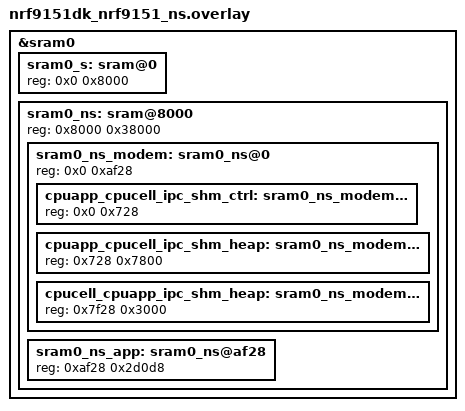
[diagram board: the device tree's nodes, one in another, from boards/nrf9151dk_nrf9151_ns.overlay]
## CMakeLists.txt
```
#
# Copyright (c) 2026 Nordic Semiconductor ASA
#
# SPDX-License-Identifier: LicenseRef-Nordic-5-Clause
#

cmake_minimum_required(VERSION 3.20.0)

find_package(Zephyr REQUIRED HINTS $ENV{ZEPHYR_BASE})
project(dect_tether_ipv6)

target_include_directories(app PRIVATE
  ${ZEPHYR_NRF_MODULE_DIR}/subsys/net/lib/dect/dect_tether_ipv6
)

target_sources(app PRIVATE src/main.c)
target_sources_ifdef(CONFIG_SAMPLE_DECT_TETHER_IPV6_MDNS_DNS_SD app PRIVATE
  src/mdns_dns_sd_listen.c
)
```

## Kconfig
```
#
# Copyright (c) 2026 Nordic Semiconductor ASA
#
# SPDX-License-Identifier: LicenseRef-Nordic-5-Clause
#

source "Kconfig.zephyr"

config SAMPLE_DECT_TETHER_IPV6_MDNS_DNS_SD
	bool "Advertise _dect-nr._udp on dect0 (mDNS DNS-SD, like dect_shell)"
	depends on MDNS_RESPONDER_DNS_SD
	help
	  Binds a UDP socket on the DECT interface and registers mDNS DNS-SD for
	  _dect-nr._udp.local so peers on DECT can browse this device (e.g. avahi-browse).
	  Enable CONFIG_NET_HOSTNAME and stack options via mdns.conf.

if SAMPLE_DECT_TETHER_IPV6_MDNS_DNS_SD

config SAMPLE_DECT_TETHER_IPV6_MDNS_DNS_SD_PORT
	int "UDP port for mDNS DNS-SD stub socket on dect0"
	default 4700
	range 1 65535
	help
	  Port bound on dect0 so dns_sd port_in_use checks succeed. Must match dns_sd_rec.port.

endif # SAMPLE_DECT_TETHER_IPV6_MDNS_DNS_SD

module = SAMPLE_DECT_TETHER_IPV6
module-str = DECT IPv6 tethering sample
source "${ZEPHYR_BASE}/subsys/logging/Kconfig.template.log_config"
```

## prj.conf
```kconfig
#
# Copyright (c) 2026 Nordic Semiconductor ASA
#
# SPDX-License-Identifier: LicenseRef-Nordic-5-Clause
#

CONFIG_TFM_PROFILE_TYPE_MINIMAL=y

CONFIG_DECT=y
CONFIG_DECT_DEFAULT_DEV_TYPE_PT=y
CONFIG_DECT_CLUSTER_MAX_CHILD_ASSOCIATION_COUNT=2

CONFIG_NRF_MODEM_LIB=y
CONFIG_NRF_MODEM_LINK_BINARY_DECT=y
CONFIG_NRF_MODEM_LIB_ON_FAULT_APPLICATION_SPECIFIC=y

CONFIG_DECT_MDM=y
CONFIG_DECT_MDM_DRIVER_NRF=y
CONFIG_DECT_MDM_NRF_CTRL_THREAD_STACK_SIZE=3584

CONFIG_NETWORKING=y
CONFIG_NET_NATIVE=y
CONFIG_NET_IPV4=n
CONFIG_NET_IPV6=y
CONFIG_NET_UDP=y
CONFIG_NET_MGMT=y
CONFIG_NET_MGMT_EVENT=y
CONFIG_NET_MGMT_EVENT_INFO=y
CONFIG_NET_MGMT_EVENT_INFO_DEFAULT_DATA_SIZE=208

CONFIG_NET_L2_DECT=y
CONFIG_NET_L2_DECT_MGMT=y
CONFIG_NET_L2_DECT_BR=n
CONFIG_NET_CONNECTION_MANAGER=y
CONFIG_NET_CONNECTION_MANAGER_MONITOR_STACK_SIZE=2560
CONFIG_NET_L2_DECT_CONN_MGR_AUTO_CONNECT=y
CONFIG_NET_L2_DECT_CONN_MGR_CONNECTION_PERSISTENCE=y

CONFIG_NET_L2_DECT_ULA=y
CONFIG_NET_L2_DECT_ULA_PREFIX="fdde:ad00:0000::"

CONFIG_NET_IPV6_FORWARDING=y

CONFIG_DECT_TETHER_IPV6_LIB=y
CONFIG_DECT_TETHER_IPV6_LOG_LEVEL_INF=y

CONFIG_MODEM_ANTENNA=n
CONFIG_MODEM_INFO=y
CONFIG_MODEM_INFO_ADD_NETWORK=n
CONFIG_MODEM_INFO_ADD_SIM=n

CONFIG_NET_SOCKETS=y
CONFIG_NET_SOCKETS_OFFLOAD=n
CONFIG_POSIX_API=y
CONFIG_NET_IF_MAX_IPV6_COUNT=6
CONFIG_NET_IF_UNICAST_IPV6_ADDR_COUNT=6
CONFIG_NET_IF_MCAST_IPV6_ADDR_COUNT=10
CONFIG_NET_IF_IPV6_PREFIX_COUNT=4
CONFIG_NET_INTERFACE_NAME=y
CONFIG_NET_MAX_CONTEXTS=12
CONFIG_NET_MAX_CONN=12

CONFIG_NET_RX_STACK_SIZE=4096
CONFIG_NET_TX_STACK_SIZE=4096
CONFIG_SYSTEM_WORKQUEUE_STACK_SIZE=8192

CONFIG_NET_BUF=y
CONFIG_NET_BUF_DATA_SIZE=128

CONFIG_NET_PKT_RX_COUNT=32
CONFIG_NET_PKT_TX_COUNT=64
CONFIG_NET_BUF_RX_COUNT=32
CONFIG_NET_BUF_TX_COUNT=64
CONFIG_NET_BUF_POOL_USAGE=y

CONFIG_NET_IPV6_NBR_CACHE=y
CONFIG_NET_IPV6_MAX_NEIGHBORS=10
CONFIG_NET_IPV6_ND=y

CONFIG_NET_MGMT_EVENT_STACK_SIZE=4608
CONFIG_NET_MGMT_EVENT_QUEUE_SIZE=30
CONFIG_NET_MGMT_EVENT_QUEUE_TIMEOUT=5000

CONFIG_NET_STATISTICS=y

CONFIG_SHELL=y
CONFIG_GETOPT_LONG=y
CONFIG_SHELL_PROMPT_UART="dect_tether_v6:~$ "
CONFIG_SHELL_BACKEND_SERIAL=y
CONFIG_SHELL_STACK_SIZE=9216
CONFIG_SHELL_CMD_BUFF_SIZE=4096
CONFIG_SHELL_ARGC_MAX=40
CONFIG_SHELL_BACKEND_SERIAL_RX_RING_BUFFER_SIZE=512
CONFIG_SHELL_BACKEND_SERIAL_API_INTERRUPT_DRIVEN=y
CONFIG_NET_SHELL=y
CONFIG_DECT_L2_SHELL_LIB=y
CONFIG_SHELL_LOG_BACKEND=y
CONFIG_LOG_BACKEND_UART=n

CONFIG_NET_DRIVERS=y
CONFIG_SERIAL=y

CONFIG_FLASH=y
CONFIG_FLASH_MAP=y
CONFIG_MPU_ALLOW_FLASH_WRITE=y
CONFIG_NVS=y
CONFIG_SETTINGS=y
CONFIG_SETTINGS_NVS=y

CONFIG_MAIN_STACK_SIZE=4096
CONFIG_ISR_STACK_SIZE=2048
CONFIG_HEAP_MEM_POOL_SIZE=25600
CONFIG_LOG=y
CONFIG_ASSERT=y

CONFIG_DK_LIBRARY=y
```

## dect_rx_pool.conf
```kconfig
# Copyright (c) 2026 Nordic Semiconductor ASA
# SPDX-License-Identifier: LicenseRef-Nordic-5-Clause
#
# DECT-private RX net_pkt/net_buf pool for dect_tether_ipv6.
#
# Append last in EXTRA_CONF_FILE, e.g.
#   eth_common.conf;eth_w5500.conf;dect_rx_pool.conf
#
# Why: this sample acts as the PT — DECT TX is the hot path (PC eth0 RX ->
# DECT TX uplink to FT), so the modem SHMEM split in prj.conf is
# TX-heavy. However, sustained PC->server uplink generates back-to-back
# TCP ACK bursts that arrive as small (60-96 B) DECT RX frames; those
# bursts saturate the private slab faster than the DLC RX thread can
# drain it. Sizing here is for burst depth (PKT_COUNT), not byte volume —
# fragment count can stay close to 1:1 since ACK-sized frames fit in one
# 256 B fragment.
#
# Tune _PKT_COUNT / _BUF_COUNT / _BUF_SIZE if "dect_mdm rx_pool" shows
# MaxUsed == Total under sustained PC->server traffic.
#
# Runtime inspection:
#   uart:~$ dect_mdm rx_pool

CONFIG_DECT_MDM_RX_PRIVATE_POOL=y

CONFIG_DECT_MDM_RX_PRIVATE_PKT_COUNT=35
CONFIG_DECT_MDM_RX_PRIVATE_BUF_COUNT=44
CONFIG_DECT_MDM_RX_PRIVATE_BUF_SIZE=128

# RX pipeline queues (event slab + msgq) must exceed PRIVATE_PKT_COUNT to
# avoid head-of-line blocking when the slab is fully in flight.
CONFIG_DECT_MDM_NRF_RX_EVENT_POOL_COUNT=40
CONFIG_DECT_MDM_NRF_RX_MSGQ_SIZE=40

# Visibility for the "dect_mdm rx_pool" shell:
CONFIG_NET_BUF_POOL_USAGE=y
CONFIG_MEM_SLAB_TRACE_MAX_UTILIZATION=y
```

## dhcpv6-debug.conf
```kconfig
# Copyright (c) 2026 Nordic Semiconductor ASA
#
# SPDX-License-Identifier: LicenseRef-Nordic-5-Clause
#
# DHCPv6 tether debugging: log each datagram received on UDP 547 and extra DBG
# lines from dect_tether_ipv6 (e.g. DHCP drops). Merge after prj.conf chain:
#
#   EXTRA_CONF_FILE="eth_common.conf;eth_w5500.conf;dhcpv6-debug.conf"
#
# Disable for production (Renew traffic can spam UART).

CONFIG_DECT_TETHER_IPV6_DHCPV6_RX_LOG=y
CONFIG_DECT_TETHER_IPV6_DHCPV6_TRACE=y
CONFIG_DECT_TETHER_IPV6_LOG_LEVEL_DBG=y
```

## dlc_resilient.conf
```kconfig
# Copyright (c) 2026 Nordic Semiconductor ASA
# SPDX-License-Identifier: LicenseRef-Nordic-5-Clause
#
# Loss-resilient DLC profile for dect_tether_ipv6 (PT side).
#
# Append last in EXTRA_CONF_FILE, e.g.:
#   eth_common.conf;eth_w5500.conf;dlc_resilient.conf
#
# Why: the stock DLC defaults (60 s lifetime, release on first discard)
# don't suit a tether deployment. Applied to the PT's flow_config[0]
# (PT->FT uplink) at association:
#
#   * SDU lifetime = 1.5 s (NRF_MODEM_DECT_DLC_SDU_LIFETIME_1_5_S = 21):
#     large enough to absorb a few DLC retransmission rounds without
#     dropping queued payload, small enough that a broken link surfaces
#     in seconds. Lower for latency-sensitive workloads instead.
#
#   * discard_release_assoc_count = 20: release only after 20 consecutive
#     DLC_DISCARD_TIMER_EXPIRED responses (counter resets on successful
#     TX); ~30 s worst case at the lifetime above. 0 = never release. The
#     matching FT-side overlay (dect_shell) uses 2.5 s; the two sides do
#     NOT need matching values.
#
# Both are runtime-tunable via the DECT L2 shell:
#   uart:~$ dect sett --dlc_sdu_lifetime 21
#   uart:~$ dect sett --dlc_discard_release_assoc_count 20
#   uart:~$ dect sett --read
#
# Valid sdu_lifetime: 1..31 (0.5 ms..60 s) or 255 for INFINITY.

CONFIG_DECT_MDM_NRF_DLC_SDU_LIFETIME=21
CONFIG_DECT_MDM_NRF_DLC_DISCARD_TIMER_RELEASE_ASSOC_COUNT=20
```

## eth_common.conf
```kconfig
# Copyright (c) 2026 Nordic Semiconductor ASA
#
# SPDX-License-Identifier: LicenseRef-Nordic-5-Clause
#
# Shared Ethernet shield Kconfig for dect_tether_ipv6 sample.
#
# EXTRA_CONF_FILE merge order (omit mDNS layers when not needed):
#   eth_common.conf -> eth_w5500.conf ->
#   mdns-common.conf -> mdns.conf -> eth_mdns.conf -> mdns_forward.conf -> optional extras
#
# From the sample directory (Ethernet only, no mDNS):
#   cd nrf/samples/dect/dect_tether_ipv6
#   west build -p -b nrf9151dk/nrf9151/ns --
#     -DSHIELD=arceli_eth_w5500
#     -DEXTRA_CONF_FILE="eth_common.conf;eth_w5500.conf"
#     -DEXTRA_DTC_OVERLAY_FILE=w5500-static-mac.overlay
#
# With mDNS responder on eth0 and dect0 (append mdns-common.conf, mdns.conf,
# eth_mdns.conf; add mdns_forward.conf for the eth0 <-> dect0 tap):
#   west build -p -b nrf9151dk/nrf9151/ns --
#     -DSHIELD=arceli_eth_w5500
#     -DEXTRA_CONF_FILE="eth_common.conf;eth_w5500.conf;mdns-common.conf;mdns.conf;eth_mdns.conf"
#     -DEXTRA_DTC_OVERLAY_FILE=w5500-static-mac.overlay
#
# For a random MAC each boot, use -DEXTRA_DTC_OVERLAY_FILE=w5500.overlay instead.
# For periodic unsolicited NA toward the tethered host, append eth_unsol_na.conf.
#
# Windows 11: RA-learned ::/0 often drops after ~30 s NUD. On the PC use a persistent
# static ::/0 (elevated PowerShell netsh) — see README "Optional static default
# gateway (Windows 11)". Or append eth_max_connectivity.conf (longer NUD interval).
#

# Unicast RA to RS source (RFC 4861); helps Windows install ::/0 at link-up.
CONFIG_DECT_TETHER_IPV6_RA_RS_UNICAST=y

CONFIG_SPI=y

CONFIG_ETH_DRIVER=y

CONFIG_NET_L2_ETHERNET=y
CONFIG_NET_L2_ETHERNET_MGMT=y

CONFIG_NET_L2_DECT_MTU=1500

# Using DECT and Ethernet RX threads
#CONFIG_NET_TC_TX_COUNT=0
#CONFIG_NET_TC_RX_COUNT=0

CONFIG_NET_PKT_TX_COUNT=10
CONFIG_NET_BUF_TX_COUNT=20

CONFIG_NET_PKT_RX_COUNT=30
CONFIG_NET_BUF_RX_COUNT=200

CONFIG_NET_LOG=y
CONFIG_ETHERNET_LOG_LEVEL_INF=y
CONFIG_NET_L2_ETHERNET_LOG_LEVEL_INF=y
# Surface "iface N pkt 0x... send failure status -E*" warnings (e.g. W5500 -EIO
# bursts) on this sample; otherwise net_if defaults below WRN and those
# warnings are silently dropped.
CONFIG_NET_IF_LOG_LEVEL_WRN=y

CONFIG_NET_MGMT_EVENT_QUEUE_SIZE=30

# dect0 + eth0
CONFIG_NET_IF_MAX_IPV6_COUNT=2
CONFIG_NET_IF_UNICAST_IPV6_ADDR_COUNT=3
CONFIG_NET_IF_IPV6_PREFIX_COUNT=3

CONFIG_DK_LIBRARY=n
```

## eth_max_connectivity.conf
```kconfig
# Copyright (c) 2026 Nordic Semiconductor ASA
#
# SPDX-License-Identifier: LicenseRef-Nordic-5-Clause
#
# Maximum-connectivity timer overlay for dect_tether_ipv6.
#
# Include AFTER eth_common.conf to override its test-oriented defaults:
#   -DEXTRA_CONF_FILE="eth_common.conf;eth_w5500.conf;eth_max_connectivity.conf"
#
# DO NOT include eth_unsol_na.conf together with this file unless you need it.
#
# Long REACHABLE_TIME and router/DHCP lifetimes reduce how often hosts run NUD
# and how often router_lifetime must be refreshed. Periodic multicast RAs
# (RA_UNSOLICIT_MS, default 60 s) remain the only RA refresh path.

# RFC 4861 §6.2.1 maximum: 3 600 000 ms.
CONFIG_DECT_TETHER_IPV6_RA_REACHABLE_TIME_MS=3600000

# RFC 4861 §4.2 maximum: 65535 s (~18 h).
CONFIG_DECT_TETHER_IPV6_RA_ROUTER_LIFETIME=65535

# DHCPv6 lease timers aligned with a long-running session.
CONFIG_DECT_TETHER_IPV6_DHCPV6_ADDR_PREFERRED_LIFETIME=86400
CONFIG_DECT_TETHER_IPV6_DHCPV6_ADDR_VALID_LIFETIME=172800
CONFIG_DECT_TETHER_IPV6_DHCPV6_T1=1800
CONFIG_DECT_TETHER_IPV6_DHCPV6_T2=2880

# PIO lifetimes matched to DHCPv6 address lifetimes.
CONFIG_DECT_TETHER_IPV6_RA_PIO_PREFERRED_LIFETIME=86400
CONFIG_DECT_TETHER_IPV6_RA_PIO_VALID_LIFETIME=172800
```

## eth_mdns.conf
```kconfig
# Copyright (c) 2026 Nordic Semiconductor ASA
#
# SPDX-License-Identifier: LicenseRef-Nordic-5-Clause
#
# mDNS-on-Ethernet tuning for dect_tether_ipv6. Merge after :file:`eth_common.conf`,
# shield-specific :file:`eth_*.conf`, :file:`mdns-common.conf`, and :file:`mdns.conf`.
#
# From the sample directory:
#   cd nrf/samples/dect/dect_tether_ipv6
#   west build -p -b nrf9151dk/nrf9151/ns --
#     -DSHIELD=arceli_eth_w5500
#     -DEXTRA_CONF_FILE="eth_common.conf;eth_w5500.conf;mdns-common.conf;mdns.conf;eth_mdns.conf"
#     -DEXTRA_DTC_OVERLAY_FILE=w5500-static-mac.overlay
#
# With eth0 <-> dect0 mDNS tap, also merge mdns_forward.conf after this file.

# Unicast DNS on eth0 + scoped mDNS on dect0 (order: unicast first, then mDNS).
CONFIG_DNS_RESOLVER_MAX_SERVERS=3
CONFIG_DNS_SERVER1="2001:4860:4860::8888%eth0"
CONFIG_DNS_SERVER2="2001:4860:4860::8844%eth0"
CONFIG_DNS_SERVER3="[ff02::fb]:5353%dect0"

# mdns-common.conf sets CONFIG_ZVFS_POLL_MAX=10; dect0 + eth0 and three scoped DNS
# servers need more dispatcher poll slots or dns_resolve_init returns -EAGAIN.
CONFIG_ZVFS_POLL_MAX=16
```

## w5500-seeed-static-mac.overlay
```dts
/*
 * Copyright (c) 2026 Nordic Semiconductor ASA
 *
 * SPDX-License-Identifier: LicenseRef-Nordic-5-Clause
 */

/*
 * Seeed W5500 Ethernet shield on nRF9151 DK (Zephyr shield seeed_w5500).
 *
 * Build (from the sample directory):
 *   cd nrf/samples/dect/dect_tether_ipv6
 *   west build -p -b nrf9151dk/nrf9151/ns --
 *     -DSHIELD=seeed_w5500
 *     -DEXTRA_CONF_FILE="eth_common.conf;eth_w5500.conf;eth_w5500_seeed.conf"
 *     -DEXTRA_DTC_OVERLAY_FILE=w5500-seeed-static-mac.overlay
 *
 * MAC below is locally administered unicast (U/L bit set). Replace all six octets
 * per unit if several boards share one broadcast domain.
 *
 * INT pin: the WIZnet/Seeed W5500 shield routes the W5500 INTn to Arduino D2
 * through R25, and Rev 1.01 ships with R25 removed, so INTn never reaches a
 * header pin (and cannot be jumpered without soldering). Remove int-gpios so
 * the W5500 driver uses devicetree polling mode (see wiznet,w5500 binding).
 * Pair with eth_w5500_seeed.conf for a faster poll period. If your unit has R25
 * populated (real INTn on D2), omit this overlay to keep interrupt mode.
 */

&eth_w5500 {
	local-mac-address = [f6 ce 36 04 73 b1];
	/delete-property/ int-gpios;
};
```

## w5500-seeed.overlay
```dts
/*
 * Copyright (c) 2026 Nordic Semiconductor ASA
 *
 * SPDX-License-Identifier: LicenseRef-Nordic-5-Clause
 */

/*
 * Seeed W5500 Ethernet shield on nRF9151 DK (Zephyr shield seeed_w5500).
 *
 * Build (from the sample directory):
 *   cd nrf/samples/dect/dect_tether_ipv6
 *   west build -p -b nrf9151dk/nrf9151/ns --
 *     -DSHIELD=seeed_w5500
 *     -DEXTRA_CONF_FILE="eth_common.conf;eth_w5500.conf;eth_w5500_seeed.conf"
 *     -DEXTRA_DTC_OVERLAY_FILE=w5500-seeed.overlay
 *
 * For a fixed MAC, use w5500-seeed-static-mac.overlay instead.
 *
 * INT pin: the WIZnet/Seeed W5500 shield routes the W5500 INTn to Arduino D2
 * through R25, and Rev 1.01 ships with R25 removed, so INTn never reaches a
 * header pin (and cannot be jumpered without soldering). Remove int-gpios so
 * the W5500 driver uses devicetree polling mode (see wiznet,w5500 binding).
 * Pair with eth_w5500_seeed.conf for a faster poll period. If your unit has R25
 * populated (real INTn on D2), omit this overlay to keep interrupt mode.
 */

&eth_w5500 {
	zephyr,random-mac-address;
	/delete-property/ int-gpios;
};
```

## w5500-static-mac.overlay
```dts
/*
 * Copyright (c) 2026 Nordic Semiconductor ASA
 *
 * SPDX-License-Identifier: LicenseRef-Nordic-5-Clause
 */

/*
 * Arceli W5500 with fixed Ethernet MAC (alternative to w5500.overlay).
 *
 * Build: same as the Arceli Ethernet build but use this overlay instead:
 *   -DEXTRA_DTC_OVERLAY_FILE=w5500-static-mac.overlay
 *
 * MAC below is locally administered unicast (U/L bit set). Replace all six octets
 * per unit if several boards share one broadcast domain.
 */

&eth_w5500_arceli_eth_w5500 {
	local-mac-address = [f6 ce 36 04 73 b1];
	/* spi-max-frequency = <24000000>; */
};
```

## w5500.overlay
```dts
/*
 * Copyright (c) 2026 Nordic Semiconductor ASA
 *
 * SPDX-License-Identifier: LicenseRef-Nordic-5-Clause
 */

&eth_w5500_arceli_eth_w5500 {
	zephyr,random-mac-address;
	/* spi-max-frequency = <24000000>; */
};
```

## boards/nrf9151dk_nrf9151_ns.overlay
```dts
/*
 * Copyright (c) 2026 Nordic Semiconductor ASA
 *
 * SPDX-License-Identifier: LicenseRef-Nordic-5-Clause
 */

#include <samples/cellular/nrf91_no_bootloader_partitions.dtsi>

/delete-node/ &sram0_s;
/delete-node/ &sram0_ns;

&sram0 {
	/*
	 * 0x2000_0000  Secure RAM                      (   32 kB)
	 * 0x2000_8000  Non-secure RAM area             (  224 kB)
	 *   0x2000_8000  Modem shared area             ( 44840 B)
	 *     0x2000_8000  control                     (  1832 B)
	 *     0x2000_8728  app -> cell                 (   30 kB)
	 *     0x2000_ff28  cell -> app                 (   12 kB)
	 *   0x2000_cf28  Application RAM               (184536 B)
	 */
	sram0_s: sram@0 {
		reg = <0x0 0x8000>;
	};

	sram0_ns: sram@8000 {
		reg = <0x8000 0x38000>;
		#address-cells = <1>;
		#size-cells = <1>;
		ranges = <0x0 0x8000 0x38000>;

		/* Must be in first 128 kB of RAM. */
		sram0_ns_modem: sram0_ns@0 {
			/* Modem (shared) memory */
			reg = <0x0 0xaf28>;
			#address-cells = <1>;
			#size-cells = <1>;
			ranges = <0x0 0x0 0xaf28>;

			cpuapp_cpucell_ipc_shm_ctrl: sram0_ns_modem@0 {
				/* Modem IPC control */
				reg = <0x0 0x728>;
			};

			cpuapp_cpucell_ipc_shm_heap: sram0_ns_modem@728 {
				/* Modem IPC transmit */
				reg = <0x728 0x7800>;
			};

			cpucell_cpuapp_ipc_shm_heap: sram0_ns_modem@7f28 {
				/* Modem IPC receive */
				reg = <0x7f28 0x3000>;
			};
		};

		sram0_ns_app: sram0_ns@af28 {
			/* Non-Secure application memory */
			reg = <0xaf28 0x2d0d8>;
		};
	};
};
```

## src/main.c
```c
/*
 * Copyright (c) 2026 Nordic Semiconductor ASA
 *
 * SPDX-License-Identifier: LicenseRef-Nordic-5-Clause
 */

#include <zephyr/kernel.h>
#include <zephyr/logging/log.h>
#include <zephyr/net/net_if.h>

#include <modem/nrf_modem_lib.h>
#include <nrf_modem.h>

#include <net/dect/dect_net_l2.h>

#include <net/dect/dect_tether_ipv6.h>

#if defined(CONFIG_DK_LIBRARY)
#include <dk_buttons_and_leds.h>
#endif

LOG_MODULE_REGISTER(dect_tether_ipv6_sample, CONFIG_LOG_DEFAULT_LEVEL);

BUILD_ASSERT(IS_ENABLED(CONFIG_DECT_DEFAULT_DEV_TYPE_PT),
	     "dect_tether_ipv6 is a PT-only sample");

void nrf_modem_fault_handler(struct nrf_modem_fault_info *fault_info)
{
	LOG_ERR("Modem fault: reason=%d, program_counter=0x%x", fault_info->reason,
		fault_info->program_counter);
	__ASSERT(false, "Modem crash detected, halting application");
}

int main(void)
{
	int err;
	struct net_if *dect;

	LOG_INF("=== DECT host-leg IPv6 sample (device type: PT) ===");

	dect = net_if_get_first_by_type(&NET_L2_GET_NAME(DECT));
	if (dect == NULL) {
		LOG_ERR("No DECT interface found");
		return -ENODEV;
	}

	err = nrf_modem_lib_init();
	if (err != 0) {
		LOG_ERR("nrf_modem_lib_init failed: %d", err);
		return err;
	}

#if defined(CONFIG_DK_LIBRARY)
	err = dk_leds_init();
	if (err != 0) {
		LOG_WRN("dk_leds_init failed: %d", err);
	}
#endif

	err = dect_tether_ipv6_init();
	if (err != 0) {
		LOG_ERR("dect_tether_ipv6_init failed: %d", err);
		return err;
	}

	LOG_INF("dect_tether_ipv6 active (RA + DHCPv6 per Kconfig)");
	return 0;
}
```

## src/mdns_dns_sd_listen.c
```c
/*
 * Copyright (c) 2026 Nordic Semiconductor ASA
 *
 * SPDX-License-Identifier: LicenseRef-Nordic-5-Clause
 *
 * Same pattern as samples/dect/dect_shell/src/mdns/dns_sd_advertise.c: registers a
 * DNS-SD service record via mdns_responder_set_ext_records() so Zephyr's mDNS
 * responder answers PTR/SRV/TXT browse queries for _dect-nr._udp.local. mDNS on
 * UDP 5353 is handled by the stack (mdns_responder).
 *
 * A UDP socket is bound to [::]:CONFIG_SAMPLE_DECT_TETHER_IPV6_MDNS_DNS_SD_PORT
 * to satisfy Zephyr's port_in_use() guard in dns_sd_handle_ptr_query(); without
 * it the SRV is not advertised. The bind is wildcard (any interface) and done
 * once at init -- no need to wait for dect0 specifically.
 *
 * Instance name follows net_hostname_get(); the record is refreshed on dect0
 * IPv6 address changes (so records track address changes after peer sync) and
 * on dect0 up/down transitions.
 */

#include <errno.h>
#include <string.h>

#include <zephyr/init.h>
#include <zephyr/kernel.h>
#include <zephyr/logging/log.h>
#include <zephyr/net/dns_sd.h>
#include <zephyr/net/hostname.h>
#include <zephyr/net/mdns_responder.h>
#include <zephyr/net/net_if.h>
#include <zephyr/net/net_mgmt.h>
#include <zephyr/net/socket.h>
#include <zephyr/sys/atomic.h>
#include <zephyr/sys/byteorder.h>
#include <zephyr/sys/util.h>

LOG_MODULE_REGISTER(bh6_mdns, CONFIG_SAMPLE_DECT_TETHER_IPV6_LOG_LEVEL);

#define BH6_MDNS_IFACE_NAME "dect0"

static char bh6_dns_sd_instance[DNS_SD_INSTANCE_MAX_SIZE + 1];

static const uint16_t bh6_dns_sd_port_be =
	sys_cpu_to_be16((uint16_t)CONFIG_SAMPLE_DECT_TETHER_IPV6_MDNS_DNS_SD_PORT);

static struct dns_sd_rec bh6_dns_sd_rec = {
	.instance = bh6_dns_sd_instance,
	.service = "_dect-nr",
	.proto = "_udp",
	.domain = "local",
	.text = DNS_SD_EMPTY_TXT,
	.text_size = 0,
	.port = &bh6_dns_sd_port_be,
};

static K_MUTEX_DEFINE(bh6_dns_sd_mutex);

static void bh6_dns_sd_refresh(void)
{
	const char *h = net_hostname_get();
	size_t n = strlen(h);

	if (n > DNS_SD_INSTANCE_MAX_SIZE) {
		n = DNS_SD_INSTANCE_MAX_SIZE;
	}
	if (n < DNS_SD_INSTANCE_MIN_SIZE) {
		LOG_WRN("DNS-SD: hostname too short for instance label, skip");
		return;
	}

	k_mutex_lock(&bh6_dns_sd_mutex, K_FOREVER);
	memcpy(bh6_dns_sd_instance, h, n);
	bh6_dns_sd_instance[n] = '\0';
	int ret = mdns_responder_set_ext_records(&bh6_dns_sd_rec, 1);

	LOG_INF("DNS-SD: refresh instance=%s.%s.%s.local ret=%d", bh6_dns_sd_instance,
		bh6_dns_sd_rec.service, bh6_dns_sd_rec.proto, ret);
	k_mutex_unlock(&bh6_dns_sd_mutex);
}

enum bh6_dns_sd_state {
	BH6_DNS_SD_STATE_WAITING_IFACE,
	BH6_DNS_SD_STATE_ADVERTISING,
};

static atomic_t bh6_dns_sd_state = ATOMIC_INIT(BH6_DNS_SD_STATE_WAITING_IFACE);

static struct net_if *bh6_mdns_net_if(void)
{
	int idx = net_if_get_by_name(BH6_MDNS_IFACE_NAME);

	if (idx < 0) {
		return NULL;
	}

	return net_if_get_by_index(idx);
}

static void bh6_dns_sd_evt(struct net_mgmt_event_callback *cb, uint64_t mgmt_event,
			   struct net_if *iface)
{
	ARG_UNUSED(cb);

	if (iface != bh6_mdns_net_if()) {
		return;
	}

	switch (mgmt_event) {
	case NET_EVENT_IF_UP:
		if (atomic_cas(&bh6_dns_sd_state, BH6_DNS_SD_STATE_WAITING_IFACE,
			       BH6_DNS_SD_STATE_ADVERTISING)) {
			LOG_INF("DNS-SD: advertising _dect-nr._udp on %s, instance=%s (port %u)",
				BH6_MDNS_IFACE_NAME, net_hostname_get(),
				(unsigned int)CONFIG_SAMPLE_DECT_TETHER_IPV6_MDNS_DNS_SD_PORT);
		}
		bh6_dns_sd_refresh();
		break;
	case NET_EVENT_IF_DOWN:
		atomic_set(&bh6_dns_sd_state, BH6_DNS_SD_STATE_WAITING_IFACE);
		break;
	case NET_EVENT_IPV6_ADDR_ADD:
	case NET_EVENT_IPV6_ADDR_DEL:
		bh6_dns_sd_refresh();
		break;
	default:
		break;
	}
}

static struct net_mgmt_event_callback bh6_dns_sd_cb;

/* Placeholder listener: bind [::]:CONFIG_SAMPLE_DECT_TETHER_IPV6_MDNS_DNS_SD_PORT
 * and leave it open. Zephyr's dns_sd_handle_ptr_query() rejects SRV advertising
 * for a port that isn't in use; this bind satisfies that guard without spawning
 * a thread.
 */
static int bh6_dns_sd_placeholder_bind(void)
{
	struct sockaddr_in6 bind_addr = {
		.sin6_family = AF_INET6,
		.sin6_port = htons(CONFIG_SAMPLE_DECT_TETHER_IPV6_MDNS_DNS_SD_PORT),
		.sin6_addr = in6addr_any,
	};
	int sock;

	sock = zsock_socket(AF_INET6, SOCK_DGRAM, IPPROTO_UDP);
	if (sock < 0) {
		LOG_ERR("DNS-SD: placeholder socket failed (%d)", errno);
		return -errno;
	}

	if (zsock_bind(sock, (struct sockaddr *)&bind_addr, sizeof(bind_addr)) < 0) {
		LOG_ERR("DNS-SD: placeholder bind [::]:%u failed (%d)",
			(unsigned int)CONFIG_SAMPLE_DECT_TETHER_IPV6_MDNS_DNS_SD_PORT, errno);
		zsock_close(sock);
		return -errno;
	}

	LOG_INF("DNS-SD: placeholder listener bound UDP [::]:%u",
		(unsigned int)CONFIG_SAMPLE_DECT_TETHER_IPV6_MDNS_DNS_SD_PORT);
	return 0;
}

static int bh6_dns_sd_init(void)
{
	struct net_if *iface;
	int ret;

	net_mgmt_init_event_callback(&bh6_dns_sd_cb, bh6_dns_sd_evt,
				     NET_EVENT_IF_UP | NET_EVENT_IF_DOWN |
				     NET_EVENT_IPV6_ADDR_ADD | NET_EVENT_IPV6_ADDR_DEL);
	net_mgmt_add_event_callback(&bh6_dns_sd_cb);

	ret = bh6_dns_sd_placeholder_bind();
	if (ret < 0) {
		LOG_ERR("DNS-SD: placeholder bind failed (%d); SRV record will not be advertised",
			ret);
	}

	/* Register the DNS-SD record now so mdns_responder can answer as soon as
	 * dect0 is up and has an IPv6 address.
	 */
	bh6_dns_sd_refresh();

	/* If dect0 is already up before this init ran, flip state directly. */
	iface = bh6_mdns_net_if();
	if (iface != NULL && net_if_flag_is_set(iface, NET_IF_UP)) {
		atomic_set(&bh6_dns_sd_state, BH6_DNS_SD_STATE_ADVERTISING);
	}

	return 0;
}

SYS_INIT(bh6_dns_sd_init, APPLICATION, CONFIG_APPLICATION_INIT_PRIORITY);
```
